# PIC32MM0256GPM036 register map
Vendor: Microchip
Registers are 32-bit, read-write, reset 0x0 unless marked. A register's access mark holds for its fields unless they carry their own. Addresses are absolute, and some are shared; only a register's first bit layout is shown; [hi:lo] are bit positions; 'fields as' and 'values as' point back to an identical list.

## CONFIG — Configuration words, addresses in PhysicalSpace
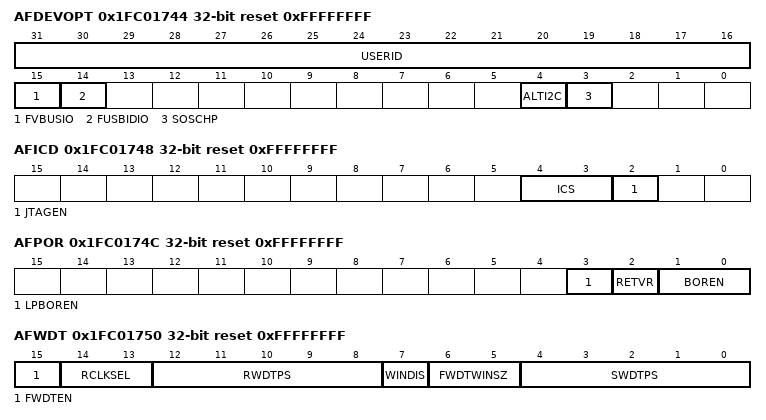
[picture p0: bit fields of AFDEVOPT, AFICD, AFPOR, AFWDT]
0x1FC01744 AFDEVOPT reset 0xFFFFFFFF
  [31:16] USERID — User ID bits
  [15] FVBUSIO — VBUS Pin Control
    0=ON (VBUS pin is controlled by port function); 1=OFF (VBUS pin is controlled by the USB module)
  [14] FUSBIDIO — USBID pin control
    0=ON (USBID pin is controlled by the port function); 1=OFF (USBID pin is controlled by the USB module)
  [4] ALTI2C — Alternate I2C1 Pins Location Enable bit
    0=ON (Alternate I2C1 pins are used); 1=OFF (Primary I2C1 pins are used)
  [3] SOSCHP — Secondary Oscillator High Power Enable bit
    0=ON (SOSC oprerates in high power mode); 1=OFF (SOSC oprerates in normal power mode.)
0x1FC01748 AFICD reset 0xFFFFFFFF
  [4:3] ICS — ICE/ICD Communication Channel Selection bits
    3=PGx1 (Communicate on PGEC1/PGED1); 2=PGx2 (Communicate on PGEC2/PGED2); 1=PGx3 (Communicate on PGEC3/PGED3); 0=NONE (Not connected)
  [2] JTAGEN — JTAG Enable bit
    1=ON (JTAG is enabled); 0=OFF (JTAG is disabled)
0x1FC0174C AFPOR reset 0xFFFFFFFF
  [3] LPBOREN — Downside Voltage Protection Enable bit
    1=ON (Low power BOR is enabled, when main BOR is disabled); 0=OFF (Low power BOR is disabled)
  [2] RETVR — Retention Voltage Regulator Enable bit
    0=ON (Retention regulator is enabled and controlled by RETEN bit during sleep); 1=OFF (Retention regulator is disabled)
  [1:0] BOREN — Brown-out Reset Enable bits
    3=BOR3 (Brown-out Reset enabled in hardware; SBOREN bit disabled); 2=BOR2 (Brown-out Reset enabled only while device active and disabled in Sleep; SBOREN bit disabled); 1=BOR1 (Brown-out Reset controlled with the SBOREN bit setting); 0=BOR0 (Brown-out Reset disabled in hardware; SBOREN bit disabled)
0x1FC01750 AFWDT reset 0xFFFFFFFF
  [15] FWDTEN — Watchdog Timer Enable bit
    1=ON (WDT is enabled); 0=OFF (WDT is disabled)
  [14:13] RCLKSEL — Run Mode Watchdog Timer Clock Source Selection bits
    0b0x=SYSCLK (Clock source is system clock); 2=FRC (Clock source is FRC oscillator); 3=LPRC (Clock source is LPRC (same as for sleep mode))
  [12:8] RWDTPS — Run Mode Watchdog Timer Postscale Selection bits
    0=PS1 (1:1); 1=PS2 (1:2); 2=PS4 (1:4); 3=PS8 (1:8); 4=PS16 (1:16); 5=PS32 (1:32); 6=PS64 (1:64); 7=PS128 (1:128); 8=PS256 (1:256); 9=PS512 (1:512); 10=PS1024 (1:1024); 11=PS2048 (1:2048); 12=PS4096 (1:4096); 13=PS8192 (1:8192); 14=PS16384 (1:16384); 15=PS32768 (1:32768); 0b1x000=PS65536 (1:65536); 0b1x001=PS131072 (1:131072); 0b1x010=PS262144 (1:262144); 0b1x011=PS524288 (1:524288); 0b1x1xx=PS1048576 (1:1048576)
  [7] WINDIS — Windowed Watchdog Timer Disable bit
    0=ON (Watchdog timer is in window mode); 1=OFF (Watchdog timer is in non-window mode)
  [6:5] FWDTWINSZ — Watchdog Timer Window Size bits
    0=PS75_0 (Watchdog timer window size is 75%); 1=PS50_0 (Watchdog timer window size is 50%); 2=PS37_5 (Watchdog timer window size is 37.5%); 3=PS25_0 (Watchdog timer window size is 25%)
  [4:0] SWDTPS — Sleep Mode Watchdog Timer Postscale Selection bits
    values as RWDTPS
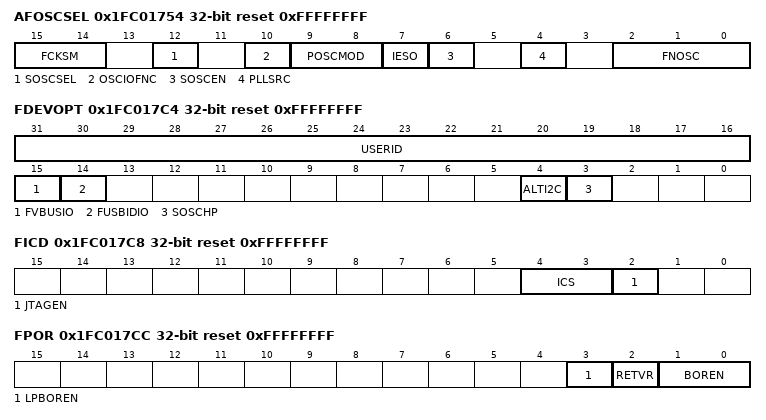
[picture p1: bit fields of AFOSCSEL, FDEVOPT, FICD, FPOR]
0x1FC01754 AFOSCSEL reset 0xFFFFFFFF
  [15:14] FCKSM — Clock Switching and Fail-Safe Clock Monitor Enable bits
    0=CSDCMD (Clock switching is disabled; Fail-safe clock monitor is disabled); 1=CSECMD (Clock switching is enabled; Fail-safe clock monitor is disabled); 2=CSDCME (Clock switching is disabled; Fail-safe clock monitor is enabled); 3=CSECME (Clock switching is enabled; Fail-safe clock monitor is enabled)
  [12] SOSCSEL — Secondary Oscillator External Clock Enable bit
    1=OFF (SOSC pins configured for Crystal mode); 0=ON (SCLKI pin configured for Digital mode)
  [10] OSCIOFNC — System Clock on CLKO Pin Enable bit
    0=ON (System clock is connected to CLKO/OSC2 pin); 1=OFF (OSCO pin operates as a normal I/O)
  [9:8] POSCMOD — Primary Oscillator Selection bit
    0=EC (External clock mode is selected); 1=XT (XT oscillator mode is selected); 2=HS (HS oscillator mode is selected); 3=OFF (Primary oscillator is disabled)
  [7] IESO — Two Speed Startup Enable bit
    1=ON (Two speed startup is enabled); 0=OFF (Two speed startup is disabled)
  [6] SOSCEN — Secondary Oscillator Enable bit
    1=ON (Secondary oscillator is enabled); 0=OFF (Secondary oscillator is disabled)
  [4] PLLSRC — System PLL Input Clock Selection bit
    0=PRI (Primary oscillator is selected as PLL reference input on device reset); 1=FRC (FRC oscillator is selected as PLL reference input on device reset)
  [2:0] FNOSC — Oscillator Selection bits
    0=FRCDIV (Fast RC oscillator (FRC) with divide-by-N); 1=PLL (Primary or FRC oscillator with PLL); 2=PRI (Primary oscillator (XT, HS, EC)); 4=SOSC (Low power secondary oscillator (SOSC)); 5=LPRC (Low power RC oscillator (LPRC))
0x1FC01758 AFSEC reset 0xFFFFFFFF
  [31] CP — Code Protection Enable bit
    0=ON (Code protection is enabled); 1=OFF (Code protection is disabled)
0x1FC01760 AFSIGN reset 0xFFFFFFFF
  [31] SIGN
    0=Reserved (This bit must be programmed to zero)
0x1FC017C4 FDEVOPT reset 0xFFFFFFFF
  fields as AFDEVOPT
0x1FC017C8 FICD reset 0xFFFFFFFF
  fields as AFICD
0x1FC017CC FPOR reset 0xFFFFFFFF
  fields as AFPOR
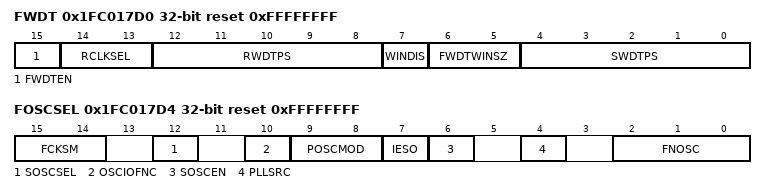
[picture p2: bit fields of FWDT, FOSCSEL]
0x1FC017D0 FWDT reset 0xFFFFFFFF
  fields as AFWDT
0x1FC017D4 FOSCSEL reset 0xFFFFFFFF
  fields as AFOSCSEL
0x1FC017D8 FSEC reset 0xFFFFFFFF
  fields as AFSEC
0x1FC017E0 FSIGN reset 0xFFFFFFFF
  [31] SIGN
    0=Reserved (This bit must be programmed to zero)
